# STM32U585 register map
File version: 2.2
CPU: CM33 r0p1, little endian, MPU, FPU, 4 interrupt priority bits
Registers are 32-bit, read-write, reset 0x0 unless marked. A register's access mark holds for its fields unless they carry their own. Offsets are from the block's base; [hi:lo] are bit positions; {n}, {i} and the like mark numbered series; 'fields as' and 'values as' point back to an identical list.

## LPDMA1
Base 0x46025000
Same registers: SEC_LPDMA1 0x56025000
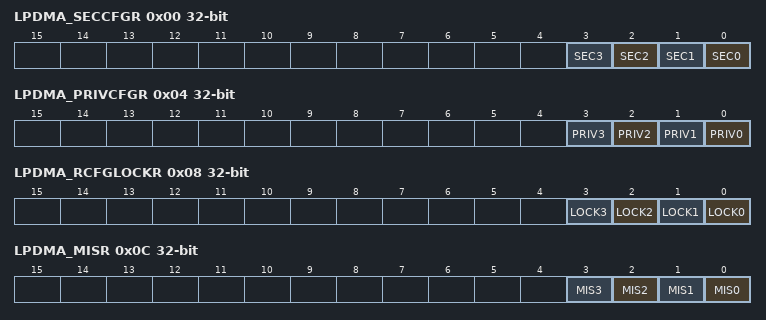
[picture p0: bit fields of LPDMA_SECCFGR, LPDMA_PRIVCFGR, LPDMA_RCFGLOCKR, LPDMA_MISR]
0x00 LPDMA_SECCFGR — LPDMA secure configuration register
  [n] SEC{n} (n=0..3)
0x04 LPDMA_PRIVCFGR — LPDMA privileged configuration register
  [n] PRIV{n} (n=0..3)
0x08 LPDMA_RCFGLOCKR — LPDMA configuration lock register
  [n] LOCK{n} (n=0..3)
0x0C LPDMA_MISR ro — LPDMA non-secure masked interrupt status register
  [n] MIS{n} (n=0..3)
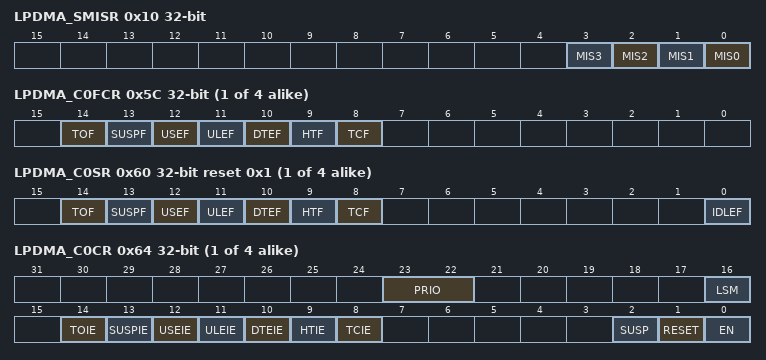
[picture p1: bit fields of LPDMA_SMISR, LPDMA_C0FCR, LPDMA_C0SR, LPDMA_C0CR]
0x10 LPDMA_SMISR ro — LPDMA secure masked interrupt status register
  [n] MIS{n} (n=0..3)
{0x50+0x80*i} LPDMA_C{i}LBAR (i=0..3) — LPDMA channel {i} linked-list base address register
  [31:16] LBA — linked-list base address of LPDMA channel x
{0x5C+0x80*i} LPDMA_C{i}FCR wo (i=0..3) — LPDMA channel {i} flag clear register
  [14] TOF — trigger overrun flag clear
    0=no effect; 1=clears the corresponding TOF flag
  [13] SUSPF — completed suspension flag clear
    0=no effect; 1=corresponding SUSPF flag cleared
  [12] USEF — user setting error flag clear
    0=no effect; 1=corresponding USEF flag cleared
  [11] ULEF — update link transfer error flag clear
    0=no effect; 1=corresponding ULEF flag cleared
  [10] DTEF — data transfer error flag clear
    0=no effect; 1=corresponding DTEF flag cleared
  [9] HTF — half transfer flag clear
    0=no effect; 1=corresponding HTF flag cleared
  [8] TCF — transfer complete flag clear
    0=no effect; 1=corresponding TCF flag cleared
{0x60+0x80*i} LPDMA_C{i}SR ro reset 0x1 (i=0..3) — LPDMA channel {i} status register
  [14] TOF — trigger overrun flag clear
    0=no effect; 1=clears the corresponding TOF flag
  [13] SUSPF — completed suspension flag
    0=no completed suspension event; 1=a completed suspension event occurred
  [12] USEF — user setting error flag
    0=no user setting error event; 1=a user setting error event occurred
  [11] ULEF — update link transfer error flag
    0=no update link transfer error event; 1=a master bus error event occurred while updating a linked-list register from memory
  [10] DTEF — data transfer error flag
    0=no data transfer error event; 1=a master bus error event occurred on a data transfer
  [9] HTF — half transfer flag
    0=no half transfer event; 1=an half transfer event occurred
  [8] TCF — transfer complete flag
    0=no transfer complete event; 1=a transfer complete event occurred
  [0] IDLEF — idle flag
    0=channel not in idle state; 1=channel in idle state
{0x64+0x80*i} LPDMA_C{i}CR access per field (i=0..3) — LPDMA channel {i} control register
  [23:22] PRIO rw — priority level of the channel x LPDMA transfer versus others
    0=low priority, low weight; 1=low priority, mid weight; 2=low priority, high weight; 3=high priority
  [16] LSM rw — Link step mode
    0=channel executed for the full linked-list and completed at the end of the last LLI (LPDMA_CxLLR=0). The 16 low-significant bits of the link address are null (LA[15:0]=0) and all the update bits are null (UT1=UB1=UT2=USA=UDA=ULL=0). Then LPDMA_CxBR1.BNDT[15:0]=0.; 1=channel executed once for the current LLI
  [14] TOIE rw — trigger overrun interrupt enable
    0=interrupt disabled; 1=interrupt enabled
  [13] SUSPIE rw — completed suspension interrupt enable
    0=interrupt disabled; 1=interrupt enabled
  [12] USEIE rw — user setting error interrupt enable
    0=interrupt disabled; 1=interrupt enabled
  [11] ULEIE rw — update link transfer error interrupt enable
    0=interrupt disabled; 1=interrupt enabled
  [10] DTEIE rw — data transfer error interrupt enable
    0=interrupt disabled; 1=interrupt enabled
  [9] HTIE rw — half transfer complete interrupt enable
    0=interrupt disabled; 1=interrupt enabled
  [8] TCIE rw — transfer complete interrupt enable
    0=interrupt disabled; 1=interrupt enabled
  [2] SUSP rw — suspend
    0=write: resume channel, read: channel not suspended; 1=write: suspend channel, read: channel suspended
  [1] RESET wo
    0=no channel reset; 1=channel reset
  [0] EN rw — enable
    0=write: ignored, read: channel disabled; 1=write: enable channel, read: channel enabled
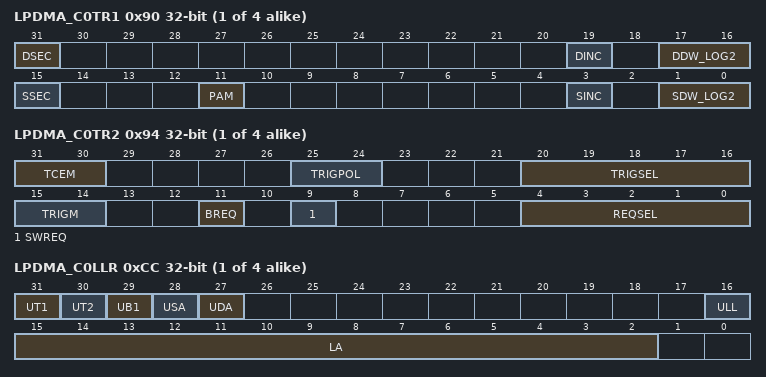
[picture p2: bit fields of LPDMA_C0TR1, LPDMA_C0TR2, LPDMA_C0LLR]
{0x90+0x80*i} LPDMA_C{i}TR1 (i=0..3) — LPDMA channel {i} transfer register 1
  [31] DSEC — security attribute of the LPDMA transfer to the destination
    0=LPDMA transfer non-secure; 1=LPDMA transfer secure
  [19] DINC — destination incrementing single
    0=fixed single; 1=contiguously incremented single
  [17:16] DDW_LOG2 — binary logarithm of the destination data width of a single in bytes
    0=byte; 1=half-word (2 bytes); 2=word (4 bytes); 3=user setting error reported and no transfer issued
  [15] SSEC — security attribute of the LPDMA transfer from the source
    0=LPDMA transfer non-secure; 1=LPDMA transfer secure
  [11] PAM — padding/alignment mode
    0=source data is transferred as right aligned, padded with 0s up to the destination data width; 1=source data is transferred as right aligned, sign extended up to the destination data width
  [3] SINC — source incrementing single
    0=fixed single; 1=contiguously incremented single
  [1:0] SDW_LOG2 — binary logarithm of the source data width of a single in bytes
    values as DDW_LOG2
{0x94+0x80*i} LPDMA_C{i}TR2 (i=0..3) — LPDMA channel {i} transfer register 2
  [31:30] TCEM — transfer complete event mode
    0=at block level (when LPDMA_CxBR1.BNDT[15:0] = 0): the complete (and the half) transfer event is generated at the (respectively half of the) end of a block; 1=same as 00; 2=at LLI level: the complete transfer event is generated at the end of the LLI transfer, including the update of the LLI if any. The half transfer event is generated at the half of the LLI data transfer (the LLI data transfer being a block transfer), if any data transfer.; 3=at channel level: the complete transfer event is generated at the end of the last LLI transfer. The half transfer event is generated at the half of the data transfer of the last LLI. The last LLI updates the link address LPDMA_CxLLR.LA[15:2] to zero and clears all the LPDMA_CxLLR update bits (UT1, UT2, UB1, USA, UDA and ULL). If the channel transfer is continuous/infinite, no event is generated.
  [25:24] TRIGPOL — trigger event polarity
    0=no trigger (masked trigger event); 1=trigger on the rising edge; 2=trigger on the falling edge; 3=same as 00
  [20:16] TRIGSEL — trigger event input selection
  [15:14] TRIGM — trigger mode
    0=at block level: the first single read of each block transfer is conditioned by one hit trigger; 1=same as 00; 2=at link level: a LLI link transfer is conditioned by one hit trigger. The LLI data transfer (if any) is not conditioned.; 3=at programmed single level: each programmed single read is conditioned by one hit trigger
  [11] BREQ — block hardware request
    0=the selected hardware request is driven by a peripheral with a hardware request/acknowledge protocol at a single level; 1=the selected hardware request is driven by a peripheral with a hardware request/acknowledge protocol at a block level (see request as a block request)
  [9] SWREQ — software request
    0=no software request. The selected hardware request REQSEL[4:0] is taken into account.; 1=software request for a memory-to-memory transfer. The default selected hardware request as per REQSEL[4:0] is ignored.
  [4:0] REQSEL — DMA hardware request selection
{0x98+0x80*i} LPDMA_C{i}BR1 (i=0..3) — LPDMA channel {i} block register 1
  [15:0] BNDT — block number of data bytes to transfer from the source
{0x9C+0x80*i} LPDMA_C{i}SAR (i=0..3) — LPDMA channel {i} source address register
  [31:0] SA — source address
{0xA0+0x80*i} LPDMA_C{i}DAR (i=0..3) — LPDMA channel {i} destination address register
  [31:0] DA — destination address
{0xCC+0x80*i} LPDMA_C{i}LLR (i=0..3) — LPDMA channel {i} linked-list address register
  [31] UT1 — Update LPDMA_CxTR1 from memory
    0=no LPDMA_CxTR1 update; 1=LPDMA_CxTR1 update
  [30] UT2 — Update LPDMA_CxTR2 from memory
    0=no LPDMA_CxTR2 update; 1=LPDMA_CxTR2 update
  [29] UB1 — Update LPDMA_CxBR1 from memory
    0=no LPDMA_CxBR1 update from memory and internally restored to the previous programmed value; 1=LPDMA_CxBR1 update
  [28] USA — update LPDMA_CxSAR from memory
    0=no LPDMA_CxSAR update; 1=LPDMA_CxSAR update
  [27] UDA — Update LPDMA_CxDAR register from memory
    0=no LPDMA_CxDAR update; 1=LPDMA_CxDAR update
  [16] ULL — Update LPDMA_CxLLR register from memory
    0=no LPDMA_CxLLR update; 1=LPDMA_CxLLR update
  [15:2] LA — pointer (16-bit low-significant address) to the next linked-list data structure
